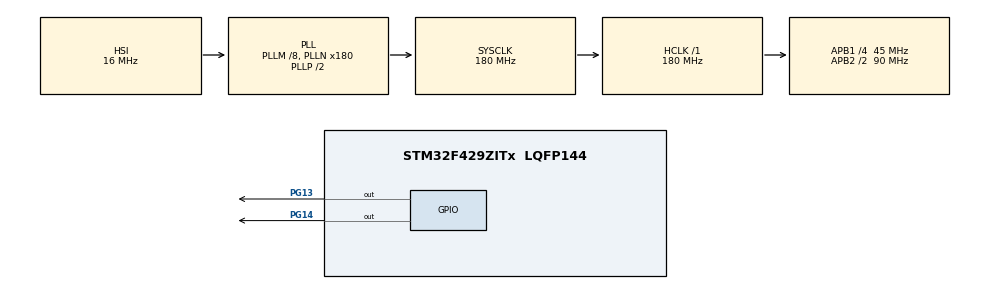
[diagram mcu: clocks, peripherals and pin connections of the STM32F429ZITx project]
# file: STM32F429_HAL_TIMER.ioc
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Mcu.Family=STM32F4
RCC.CortexFreq_Value=180000000
RCC.APB1CLKDivider=RCC_HCLK_DIV4
PG13.Signal=GPIO_Output
RCC.SYSCLKSource=RCC_SYSCLKSOURCE_PLLCLK
ProjectManager.StackSize=0x400
PA13.Signal=SYS_JTMS-SWDIO
TIM1.Prescaler=4000-1
ProjectManager.TargetToolchain=STM32CubeIDE
PH0/OSC_IN.Mode=HSE-External-Clock-Source
RCC.HCLKFreq_Value=180000000
RCC.APB2TimFreq_Value=180000000
PH1/OSC_OUT.Signal=RCC_OSC_OUT
RCC.LSE_VALUE=32768
RCC.AHBFreq_Value=180000000
PG14.Signal=GPIO_Output
RCC.HSE_VALUE=25000000
board=custom
RCC.VCOOutputFreq_Value=360000000
PH0/OSC_IN.Signal=RCC_OSC_IN
RCC.APB2Freq_Value=90000000
PA14.Mode=Serial_Wire
PA13.Mode=Serial_Wire
PH1/OSC_OUT.Mode=HSE-External-Clock-Source
Mcu.Name=STM32F429ZITx
VP_TIM1_VS_ClockSourceINT.Mode=Internal
RCC.48MHZClocksFreq_Value=90000000
RCC.SYSCLKFreq_VALUE=180000000
Mcu.Package=LQFP144
PA14.Signal=SYS_JTCK-SWCLK
ProjectManager.HeapSize=0x200
RCC.HSI_VALUE=16000000
NVIC.PriorityGroup=NVIC_PRIORITYGROUP_4
RCC.APB2CLKDivider=RCC_HCLK_DIV2
RCC.PLLM=8
RCC.PLLN=180
RCC.APB1TimFreq_Value=90000000
TIM1.Period=45000-1
RCC.APB1Freq_Value=45000000

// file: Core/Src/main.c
/* USER CODE BEGIN Header */
/**
  ******************************************************************************
  * @file           : main.c
  * @brief          : Main program body
  ******************************************************************************
  * @attention
  *
  * <h2><center>&copy; Copyright (c) 2022 STMicroelectronics.
  * All rights reserved.</center></h2>
  *
  * This software component is licensed by ST under BSD 3-Clause license,
  * the "License"; You may not use this file except in compliance with the
  * License. You may obtain a copy of the License at:
  *                        opensource.org/licenses/BSD-3-Clause
  *
  ******************************************************************************
  */
/* USER CODE END Header */
#include "main.h"

TIM_HandleTypeDef htim1;

void SystemClock_Config(void);
static void MX_GPIO_Init(void);
static void MX_TIM1_Init(void);

int main(void)
{

  /* MCU Configuration--------------------------------------------------------*/

  /* Reset of all peripherals, Initializes the Flash interface and the Systick. */
  HAL_Init();

  /* Configure the system clock */
  SystemClock_Config();

  /* Initialize all configured peripherals */
  MX_GPIO_Init();
  MX_TIM1_Init();
  /* USER CODE BEGIN 2 */
  HAL_TIM_Base_Start(&htim1);
  /* USER CODE END 2 */

  /* Infinite loop */
  while (1)
  {

    /* USER CODE BEGIN 3 */
      if(__HAL_TIM_GET_FLAG(&htim1, TIM_FLAG_UPDATE))
      {
        __HAL_TIM_CLEAR_IT(&htim1, TIM_IT_UPDATE);
        HAL_GPIO_TogglePin(GPIOG, GPIO_PIN_13 | GPIO_PIN_14);
      }
  }
  /* USER CODE END 3 */
}

void SystemClock_Config(void)
{
  RCC_OscInitTypeDef RCC_OscInitStruct = {0};
  RCC_ClkInitTypeDef RCC_ClkInitStruct = {0};

  /** Configure the main internal regulator output voltage
  */
  __HAL_RCC_PWR_CLK_ENABLE();
  __HAL_PWR_VOLTAGESCALING_CONFIG(PWR_REGULATOR_VOLTAGE_SCALE1);
  /** Initializes the RCC Oscillators according to the specified parameters
  * in the RCC_OscInitTypeDef structure.
  */
  RCC_OscInitStruct.OscillatorType = RCC_OSCILLATORTYPE_HSI;
  RCC_OscInitStruct.HSIState = RCC_HSI_ON;
  RCC_OscInitStruct.HSICalibrationValue = RCC_HSICALIBRATION_DEFAULT;
  RCC_OscInitStruct.PLL.PLLState = RCC_PLL_ON;
  RCC_OscInitStruct.PLL.PLLSource = RCC_PLLSOURCE_HSI;
  RCC_OscInitStruct.PLL.PLLM = 8;
  RCC_OscInitStruct.PLL.PLLN = 180;
  RCC_OscInitStruct.PLL.PLLP = RCC_PLLP_DIV2;
  RCC_OscInitStruct.PLL.PLLQ = 4;
  if (HAL_RCC_OscConfig(&RCC_OscInitStruct) != HAL_OK)
  {
    Error_Handler();
  }
  /** Activate the Over-Drive mode
  */
  if (HAL_PWREx_EnableOverDrive() != HAL_OK)
  {
    Error_Handler();
  }
  /** Initializes the CPU, AHB and APB buses clocks
  */
  RCC_ClkInitStruct.ClockType = RCC_CLOCKTYPE_HCLK|RCC_CLOCKTYPE_SYSCLK
                              |RCC_CLOCKTYPE_PCLK1|RCC_CLOCKTYPE_PCLK2;
  RCC_ClkInitStruct.SYSCLKSource = RCC_SYSCLKSOURCE_PLLCLK;
  RCC_ClkInitStruct.AHBCLKDivider = RCC_SYSCLK_DIV1;
  RCC_ClkInitStruct.APB1CLKDivider = RCC_HCLK_DIV4;
  RCC_ClkInitStruct.APB2CLKDivider = RCC_HCLK_DIV2;

  if (HAL_RCC_ClockConfig(&RCC_ClkInitStruct, FLASH_LATENCY_5) != HAL_OK)
  {
    Error_Handler();
  }
}

static void MX_TIM1_Init(void)
{

  TIM_ClockConfigTypeDef sClockSourceConfig = {0};
  TIM_MasterConfigTypeDef sMasterConfig = {0};

  htim1.Instance = TIM1;
  htim1.Init.Prescaler = 4000-1;
  htim1.Init.CounterMode = TIM_COUNTERMODE_UP;
  htim1.Init.Period = 45000-1;
  htim1.Init.ClockDivision = TIM_CLOCKDIVISION_DIV1;
  htim1.Init.RepetitionCounter = 0;
  htim1.Init.AutoReloadPreload = TIM_AUTORELOAD_PRELOAD_DISABLE;
  if (HAL_TIM_Base_Init(&htim1) != HAL_OK)
  {
    Error_Handler();
  }
  sClockSourceConfig.ClockSource = TIM_CLOCKSOURCE_INTERNAL;
  if (HAL_TIM_ConfigClockSource(&htim1, &sClockSourceConfig) != HAL_OK)
  {
    Error_Handler();
  }
  sMasterConfig.MasterOutputTrigger = TIM_TRGO_RESET;
  sMasterConfig.MasterSlaveMode = TIM_MASTERSLAVEMODE_DISABLE;
  if (HAL_TIMEx_MasterConfigSynchronization(&htim1, &sMasterConfig) != HAL_OK)
  {
    Error_Handler();
  }

}

static void MX_GPIO_Init(void)
{
  GPIO_InitTypeDef GPIO_InitStruct = {0};

  /* GPIO Ports Clock Enable */
  __HAL_RCC_GPIOH_CLK_ENABLE();
  __HAL_RCC_GPIOA_CLK_ENABLE();
  __HAL_RCC_GPIOG_CLK_ENABLE();

  /*Configure GPIO pin Output Level */
  HAL_GPIO_WritePin(GPIOG, GPIO_PIN_13|GPIO_PIN_14, GPIO_PIN_RESET);

  /*Configure GPIO pins : PG13 PG14 */
  GPIO_InitStruct.Pin = GPIO_PIN_13|GPIO_PIN_14;
  GPIO_InitStruct.Mode = GPIO_MODE_OUTPUT_PP;
  GPIO_InitStruct.Pull = GPIO_NOPULL;
  GPIO_InitStruct.Speed = GPIO_SPEED_FREQ_LOW;
  HAL_GPIO_Init(GPIOG, &GPIO_InitStruct);

}

void Error_Handler(void)
{
  __disable_irq();
  while (1)
  {
  }
}

/************************ (C) COPYRIGHT STMicroelectronics *****END OF FILE****/
